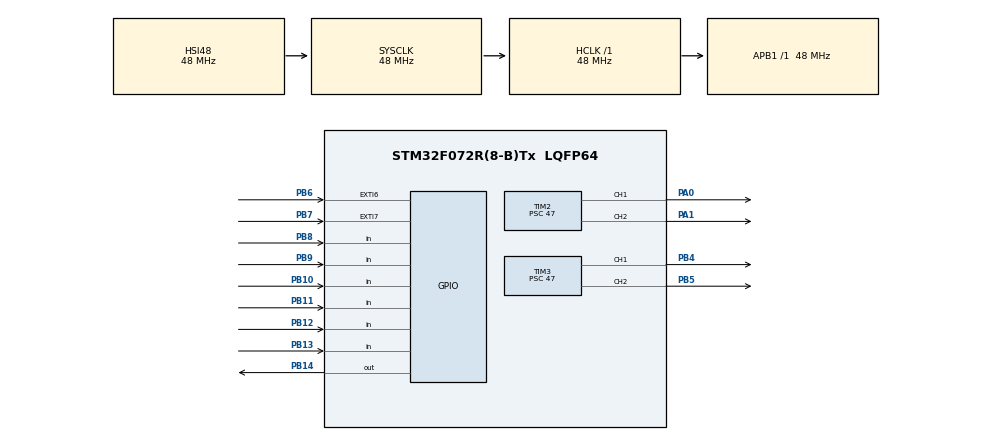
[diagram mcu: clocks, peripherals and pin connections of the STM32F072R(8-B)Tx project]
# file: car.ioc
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Mcu.Family=STM32F0
Mcu.Name=STM32F072R(8-B)Tx
Mcu.Package=LQFP64
NVIC.EXTI4_15_IRQn=true\:0\:0\:false\:false\:true\:true\:true
NVIC.TIM2_IRQn=true\:0\:0\:false\:false\:true\:true\:true
NVIC.TIM3_IRQn=true\:0\:0\:false\:false\:true\:true\:true
PA0.Signal=S_TIM2_CH1_ETR
PA1.Signal=S_TIM2_CH2
PB10.Signal=GPIO_Input
PB11.Signal=GPIO_Input
PB12.Signal=GPIO_Input
PB13.Signal=GPIO_Input
PB14.Signal=GPIO_Output
PB4.Signal=S_TIM3_CH1
PB5.Signal=S_TIM3_CH2
PB6.Signal=GPXTI6
PB7.Signal=GPXTI7
PB8.Signal=GPIO_Input
PB9.Signal=GPIO_Input
ProjectManager.HeapSize=0x200
ProjectManager.StackSize=0x400
ProjectManager.TargetToolchain=MDK-ARM V5
RCC.AHBFreq_Value=48000000
RCC.APB1Freq_Value=48000000
RCC.APB1TimFreq_Value=48000000
RCC.HCLKFreq_Value=48000000
RCC.SYSCLKFreq_VALUE=48000000
RCC.SYSCLKSource=RCC_SYSCLKSOURCE_HSI48
SH.S_TIM2_CH1_ETR.0=TIM2_CH1,PWM Generation1 CH1
SH.S_TIM2_CH2.0=TIM2_CH2,PWM Generation2 CH2
SH.S_TIM3_CH1.0=TIM3_CH1,PWM Generation1 CH1
SH.S_TIM3_CH2.0=TIM3_CH2,PWM Generation2 CH2
TIM2.Channel-PWM\ Generation1\ CH1=TIM_CHANNEL_1
TIM2.Channel-PWM\ Generation2\ CH2=TIM_CHANNEL_2
TIM2.Period=99
TIM2.Prescaler=47
TIM3.Channel-PWM\ Generation1\ CH1=TIM_CHANNEL_1
TIM3.Channel-PWM\ Generation2\ CH2=TIM_CHANNEL_2
TIM3.Period=99
TIM3.Prescaler=47
VP_TIM2_VS_ClockSourceINT.Mode=Internal
VP_TIM3_VS_ClockSourceINT.Mode=Internal
board=custom

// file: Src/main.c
/* USER CODE BEGIN Header */
/**
  ******************************************************************************
  * @file           : main.c
  * @brief          : Main program body
  ******************************************************************************
  * @attention
  *
  * <h2><center>&copy; Copyright (c) 2020 STMicroelectronics.
  * All rights reserved.</center></h2>
  *
  * This software component is licensed by ST under BSD 3-Clause license,
  * the "License"; You may not use this file except in compliance with the
  * License. You may obtain a copy of the License at:
  *                        opensource.org/licenses/BSD-3-Clause
  *
  ******************************************************************************
  */
/* USER CODE END Header */

#include "main.h"

TIM_HandleTypeDef htim2;
TIM_HandleTypeDef htim3;

void SystemClock_Config(void);
static void MX_GPIO_Init(void);
static void MX_TIM3_Init(void);
static void MX_TIM2_Init(void);

int leftcount =0,rightcount=0;
//int lflag = 0, rflag=0;
void HAL_GPIO_EXTI_Callback(uint16_t GPIO_Pin)
{
	if(GPIO_Pin==GPIO_PIN_6) //out1 left wheel
	{
		leftcount++;
	}
	if(GPIO_Pin==GPIO_PIN_7) //out2 right wheel
	{
		rightcount++;
	}
}
void HAL_TIM_PeriodElapsedCallback(TIM_HandleTypeDef *htim) //PWM
{
	if(htim->Instance==TIM3)
	{
		__HAL_TIM_SET_COMPARE(&htim2,TIM_CHANNEL_1,50);
		__HAL_TIM_SET_COMPARE(&htim3,TIM_CHANNEL_1,50);
	}
}
int main(void)
{

  /* MCU Configuration--------------------------------------------------------*/

  /* Reset of all peripherals, Initializes the Flash interface and the Systick. */
  HAL_Init();

  /* Configure the system clock */
  SystemClock_Config();

  /* Initialize all configured peripherals */
  MX_GPIO_Init();
  MX_TIM3_Init();
  MX_TIM2_Init();

  /* Infinite loop */
  /* USER CODE BEGIN WHILE */
	HAL_TIM_PWM_Start	(&htim2, TIM_CHANNEL_1) ;
	HAL_TIM_PWM_Start	(&htim2, TIM_CHANNEL_2) ;
	HAL_TIM_PWM_Start	(&htim3, TIM_CHANNEL_1) ;
	HAL_TIM_PWM_Start	(&htim3, TIM_CHANNEL_2) ;
  while (1)
  {
		__HAL_TIM_SET_COMPARE(&htim3,TIM_CHANNEL_1,50);
		__HAL_TIM_SET_COMPARE(&htim2,TIM_CHANNEL_1,50);
		/*if(leftcount == 20||rightcount == 20)
		{
			__HAL_TIM_SET_COMPARE(&htim3,TIM_CHANNEL_1,0);
			__HAL_TIM_SET_COMPARE(&htim3,TIM_CHANNEL_2,0);
			__HAL_TIM_SET_COMPARE(&htim3,TIM_CHANNEL_3,50);
			__HAL_TIM_SET_COMPARE(&htim3,TIM_CHANNEL_4,50);
		}*/
    /* USER CODE END WHILE */

  }
}

void SystemClock_Config(void)
{
  RCC_OscInitTypeDef RCC_OscInitStruct = {0};
  RCC_ClkInitTypeDef RCC_ClkInitStruct = {0};

  /** Initializes the CPU, AHB and APB busses clocks
  */
  RCC_OscInitStruct.OscillatorType = RCC_OSCILLATORTYPE_HSI48;
  RCC_OscInitStruct.HSI48State = RCC_HSI48_ON;
  RCC_OscInitStruct.PLL.PLLState = RCC_PLL_NONE;
  if (HAL_RCC_OscConfig(&RCC_OscInitStruct) != HAL_OK)
  {
    Error_Handler();
  }
  /** Initializes the CPU, AHB and APB busses clocks
  */
  RCC_ClkInitStruct.ClockType = RCC_CLOCKTYPE_HCLK|RCC_CLOCKTYPE_SYSCLK
                              |RCC_CLOCKTYPE_PCLK1;
  RCC_ClkInitStruct.SYSCLKSource = RCC_SYSCLKSOURCE_HSI48;
  RCC_ClkInitStruct.AHBCLKDivider = RCC_SYSCLK_DIV1;
  RCC_ClkInitStruct.APB1CLKDivider = RCC_HCLK_DIV1;

  if (HAL_RCC_ClockConfig(&RCC_ClkInitStruct, FLASH_LATENCY_1) != HAL_OK)
  {
    Error_Handler();
  }
}

static void MX_TIM2_Init(void)
{

  TIM_ClockConfigTypeDef sClockSourceConfig = {0};
  TIM_MasterConfigTypeDef sMasterConfig = {0};
  TIM_OC_InitTypeDef sConfigOC = {0};

  htim2.Instance = TIM2;
  htim2.Init.Prescaler = 47;
  htim2.Init.CounterMode = TIM_COUNTERMODE_UP;
  htim2.Init.Period = 99;
  htim2.Init.ClockDivision = TIM_CLOCKDIVISION_DIV1;
  htim2.Init.AutoReloadPreload = TIM_AUTORELOAD_PRELOAD_DISABLE;
  if (HAL_TIM_Base_Init(&htim2) != HAL_OK)
  {
    Error_Handler();
  }
  sClockSourceConfig.ClockSource = TIM_CLOCKSOURCE_INTERNAL;
  if (HAL_TIM_ConfigClockSource(&htim2, &sClockSourceConfig) != HAL_OK)
  {
    Error_Handler();
  }
  if (HAL_TIM_PWM_Init(&htim2) != HAL_OK)
  {
    Error_Handler();
  }
  sMasterConfig.MasterOutputTrigger = TIM_TRGO_RESET;
  sMasterConfig.MasterSlaveMode = TIM_MASTERSLAVEMODE_DISABLE;
  if (HAL_TIMEx_MasterConfigSynchronization(&htim2, &sMasterConfig) != HAL_OK)
  {
    Error_Handler();
  }
  sConfigOC.OCMode = TIM_OCMODE_PWM1;
  sConfigOC.Pulse = 0;
  sConfigOC.OCPolarity = TIM_OCPOLARITY_HIGH;
  sConfigOC.OCFastMode = TIM_OCFAST_DISABLE;
  if (HAL_TIM_PWM_ConfigChannel(&htim2, &sConfigOC, TIM_CHANNEL_1) != HAL_OK)
  {
    Error_Handler();
  }
  if (HAL_TIM_PWM_ConfigChannel(&htim2, &sConfigOC, TIM_CHANNEL_2) != HAL_OK)
  {
    Error_Handler();
  }
  HAL_TIM_MspPostInit(&htim2);

}

static void MX_TIM3_Init(void)
{

  TIM_ClockConfigTypeDef sClockSourceConfig = {0};
  TIM_MasterConfigTypeDef sMasterConfig = {0};
  TIM_OC_InitTypeDef sConfigOC = {0};

  htim3.Instance = TIM3;
  htim3.Init.Prescaler = 47;
  htim3.Init.CounterMode = TIM_COUNTERMODE_UP;
  htim3.Init.Period = 99;
  htim3.Init.ClockDivision = TIM_CLOCKDIVISION_DIV1;
  htim3.Init.AutoReloadPreload = TIM_AUTORELOAD_PRELOAD_DISABLE;
  if (HAL_TIM_Base_Init(&htim3) != HAL_OK)
  {
    Error_Handler();
  }
  sClockSourceConfig.ClockSource = TIM_CLOCKSOURCE_INTERNAL;
  if (HAL_TIM_ConfigClockSource(&htim3, &sClockSourceConfig) != HAL_OK)
  {
    Error_Handler();
  }
  if (HAL_TIM_PWM_Init(&htim3) != HAL_OK)
  {
    Error_Handler();
  }
  sMasterConfig.MasterOutputTrigger = TIM_TRGO_RESET;
  sMasterConfig.MasterSlaveMode = TIM_MASTERSLAVEMODE_DISABLE;
  if (HAL_TIMEx_MasterConfigSynchronization(&htim3, &sMasterConfig) != HAL_OK)
  {
    Error_Handler();
  }
  sConfigOC.OCMode = TIM_OCMODE_PWM1;
  sConfigOC.Pulse = 0;
  sConfigOC.OCPolarity = TIM_OCPOLARITY_HIGH;
  sConfigOC.OCFastMode = TIM_OCFAST_DISABLE;
  if (HAL_TIM_PWM_ConfigChannel(&htim3, &sConfigOC, TIM_CHANNEL_1) != HAL_OK)
  {
    Error_Handler();
  }
  if (HAL_TIM_PWM_ConfigChannel(&htim3, &sConfigOC, TIM_CHANNEL_2) != HAL_OK)
  {
    Error_Handler();
  }
  HAL_TIM_MspPostInit(&htim3);

}

static void MX_GPIO_Init(void)
{
  GPIO_InitTypeDef GPIO_InitStruct = {0};

  /* GPIO Ports Clock Enable */
  __HAL_RCC_GPIOA_CLK_ENABLE();
  __HAL_RCC_GPIOB_CLK_ENABLE();

  /*Configure GPIO pin Output Level */
  HAL_GPIO_WritePin(GPIOB, GPIO_PIN_14, GPIO_PIN_RESET);

  /*Configure GPIO pins : PB10 PB11 PB12 PB13
                           PB8 PB9 */
  GPIO_InitStruct.Pin = GPIO_PIN_10|GPIO_PIN_11|GPIO_PIN_12|GPIO_PIN_13
                          |GPIO_PIN_8|GPIO_PIN_9;
  GPIO_InitStruct.Mode = GPIO_MODE_INPUT;
  GPIO_InitStruct.Pull = GPIO_NOPULL;
  HAL_GPIO_Init(GPIOB, &GPIO_InitStruct);

  /*Configure GPIO pin : PB14 */
  GPIO_InitStruct.Pin = GPIO_PIN_14;
  GPIO_InitStruct.Mode = GPIO_MODE_OUTPUT_PP;
  GPIO_InitStruct.Pull = GPIO_NOPULL;
  GPIO_InitStruct.Speed = GPIO_SPEED_FREQ_LOW;
  HAL_GPIO_Init(GPIOB, &GPIO_InitStruct);

  /*Configure GPIO pins : PB6 PB7 */
  GPIO_InitStruct.Pin = GPIO_PIN_6|GPIO_PIN_7;
  GPIO_InitStruct.Mode = GPIO_MODE_IT_RISING;
  GPIO_InitStruct.Pull = GPIO_NOPULL;
  HAL_GPIO_Init(GPIOB, &GPIO_InitStruct);

  /* EXTI interrupt init*/
  HAL_NVIC_SetPriority(EXTI4_15_IRQn, 0, 0);
  HAL_NVIC_EnableIRQ(EXTI4_15_IRQn);

}

void Error_Handler(void)
{
}

/************************ (C) COPYRIGHT STMicroelectronics *****END OF FILE****/
